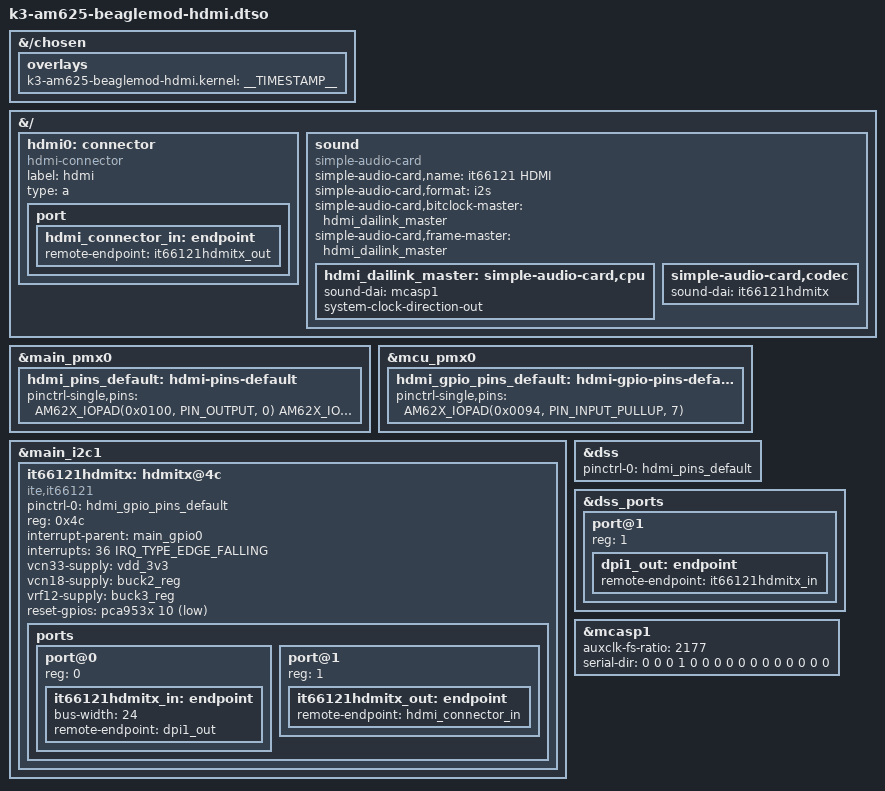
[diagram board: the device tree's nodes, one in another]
// SPDX-License-Identifier: GPL-2.0
/*
 * Copyright (C) 2022 Texas Instruments Incorporated - https://www.ti.com/
 */

/dts-v1/;
/plugin/;

#include "k3-pinctrl.h"
#include <dt-bindings/gpio/gpio.h>
#include <dt-bindings/interrupt-controller/irq.h>

/*
 * Helper to show loaded overlays under: /proc/device-tree/chosen/overlays/
 */
&{/chosen} {
	overlays {
		k3-am625-beaglemod-hdmi.kernel = __TIMESTAMP__;
	};
};

&{/} {
	hdmi0: connector {
		compatible = "hdmi-connector";
		label = "hdmi";
		type = "a";
		port {
			hdmi_connector_in: endpoint {
				remote-endpoint = <&it66121hdmitx_out>;
			};
		};
	};

	sound {
		compatible = "simple-audio-card";
		simple-audio-card,name = "it66121 HDMI";
		simple-audio-card,format = "i2s";
		simple-audio-card,bitclock-master = <&hdmi_dailink_master>;
		simple-audio-card,frame-master = <&hdmi_dailink_master>;

		hdmi_dailink_master: simple-audio-card,cpu {
			sound-dai = <&mcasp1>;
			system-clock-direction-out;
		};

		simple-audio-card,codec {
			sound-dai = <&it66121hdmitx>;
		};
	};
};

&main_pmx0 {
	hdmi_pins_default: hdmi-pins-default {
		pinctrl-single,pins = <
			AM62X_IOPAD(0x0100, PIN_OUTPUT, 0) /* (AC25) VOUT0_VSYNC */
			AM62X_IOPAD(0x00f8, PIN_OUTPUT, 0) /* (AB24) VOUT0_HSYNC */
			AM62X_IOPAD(0x0104, PIN_OUTPUT, 0) /* (AC24) VOUT0_PCLK */
			AM62X_IOPAD(0x00fc, PIN_OUTPUT, 0) /* (Y20) VOUT0_DE */
			AM62X_IOPAD(0x00b8, PIN_OUTPUT, 0) /* (U22) VOUT0_DATA0 */
			AM62X_IOPAD(0x00bc, PIN_OUTPUT, 0) /* (V24) VOUT0_DATA1 */
			AM62X_IOPAD(0x00c0, PIN_OUTPUT, 0) /* (W25) VOUT0_DATA2 */
			AM62X_IOPAD(0x00c4, PIN_OUTPUT, 0) /* (W24) VOUT0_DATA3 */
			AM62X_IOPAD(0x00c8, PIN_OUTPUT, 0) /* (Y25) VOUT0_DATA4 */
			AM62X_IOPAD(0x00cc, PIN_OUTPUT, 0) /* (Y24) VOUT0_DATA5 */
			AM62X_IOPAD(0x00d0, PIN_OUTPUT, 0) /* (Y23) VOUT0_DATA6 */
			AM62X_IOPAD(0x00d4, PIN_OUTPUT, 0) /* (AA25) VOUT0_DATA7 */
			AM62X_IOPAD(0x00d8, PIN_OUTPUT, 0) /* (V21) VOUT0_DATA8 */
			AM62X_IOPAD(0x00dc, PIN_OUTPUT, 0) /* (W21) VOUT0_DATA9 */
			AM62X_IOPAD(0x00e0, PIN_OUTPUT, 0) /* (V20) VOUT0_DATA10 */
			AM62X_IOPAD(0x00e4, PIN_OUTPUT, 0) /* (AA23) VOUT0_DATA11 */
			AM62X_IOPAD(0x00e8, PIN_OUTPUT, 0) /* (AB25) VOUT0_DATA12 */
			AM62X_IOPAD(0x00ec, PIN_OUTPUT, 0) /* (AA24) VOUT0_DATA13 */
			AM62X_IOPAD(0x00f0, PIN_OUTPUT, 0) /* (Y22) VOUT0_DATA14 */
			AM62X_IOPAD(0x00f4, PIN_OUTPUT, 0) /* (AA21) VOUT0_DATA15 */
			AM62X_IOPAD(0x005c, PIN_OUTPUT, 1) /* (R24) GPMC0_AD8.VOUT0_DATA16 */
			AM62X_IOPAD(0x0060, PIN_OUTPUT, 1) /* (R25) GPMC0_AD9.VOUT0_DATA17 */
		>;
	};
};

&mcu_pmx0 {
	hdmi_gpio_pins_default: hdmi-gpio-pins-default {
		pinctrl-single,pins = <
			AM62X_IOPAD(0x0094, PIN_INPUT_PULLUP, 7) /* (N20) GPMC0_BE1n.GPIO0_36 */
		>;
	};
};

&main_i2c1 {
	status = "okay";
	#address-cells = <1>;
	#size-cells = <0>;

	it66121hdmitx: hdmitx@4c {
		#sound-dai-cells = <0>;
		compatible = "ite,it66121";
		pinctrl-names = "default";
		pinctrl-0 = <&hdmi_gpio_pins_default>;
		reg = <0x4c>;

		interrupt-parent = <&main_gpio0>;
		interrupts = <36 IRQ_TYPE_EDGE_FALLING>;

		vcn33-supply = <&vdd_3v3>;
		vcn18-supply = <&buck2_reg>;
		vrf12-supply = <&buck3_reg>;

		reset-gpios = <&pca953x 10 GPIO_ACTIVE_LOW>;

		ports {
			#address-cells = <1>;
			#size-cells = <0>;

			port@0 {
				reg = <0>;

				it66121hdmitx_in: endpoint {
					bus-width = <24>;
					remote-endpoint = <&dpi1_out>;
				};
			};

			port@1 {
				reg = <1>;

				it66121hdmitx_out: endpoint {
					remote-endpoint = <&hdmi_connector_in>;
				};
			};
		};
	};
};

&dss {
	pinctrl-names = "default";
	pinctrl-0 = <&hdmi_pins_default>;
};

&dss_ports {
	#address-cells = <1>;
	#size-cells = <0>;

	/* VP2: DPI Output */
	port@1 {
		reg = <1>;

		dpi1_out: endpoint {
			remote-endpoint = <&it66121hdmitx_in>;
		};
	};
};

&mcasp1 {
	status = "okay";
	auxclk-fs-ratio = <2177>;

	serial-dir = <  /* 0: INACTIVE, 1: TX, 2: RX */
	       0 0 0 1
	       0 0 0 0
	       0 0 0 0
	       0 0 0 0
	>;
};
